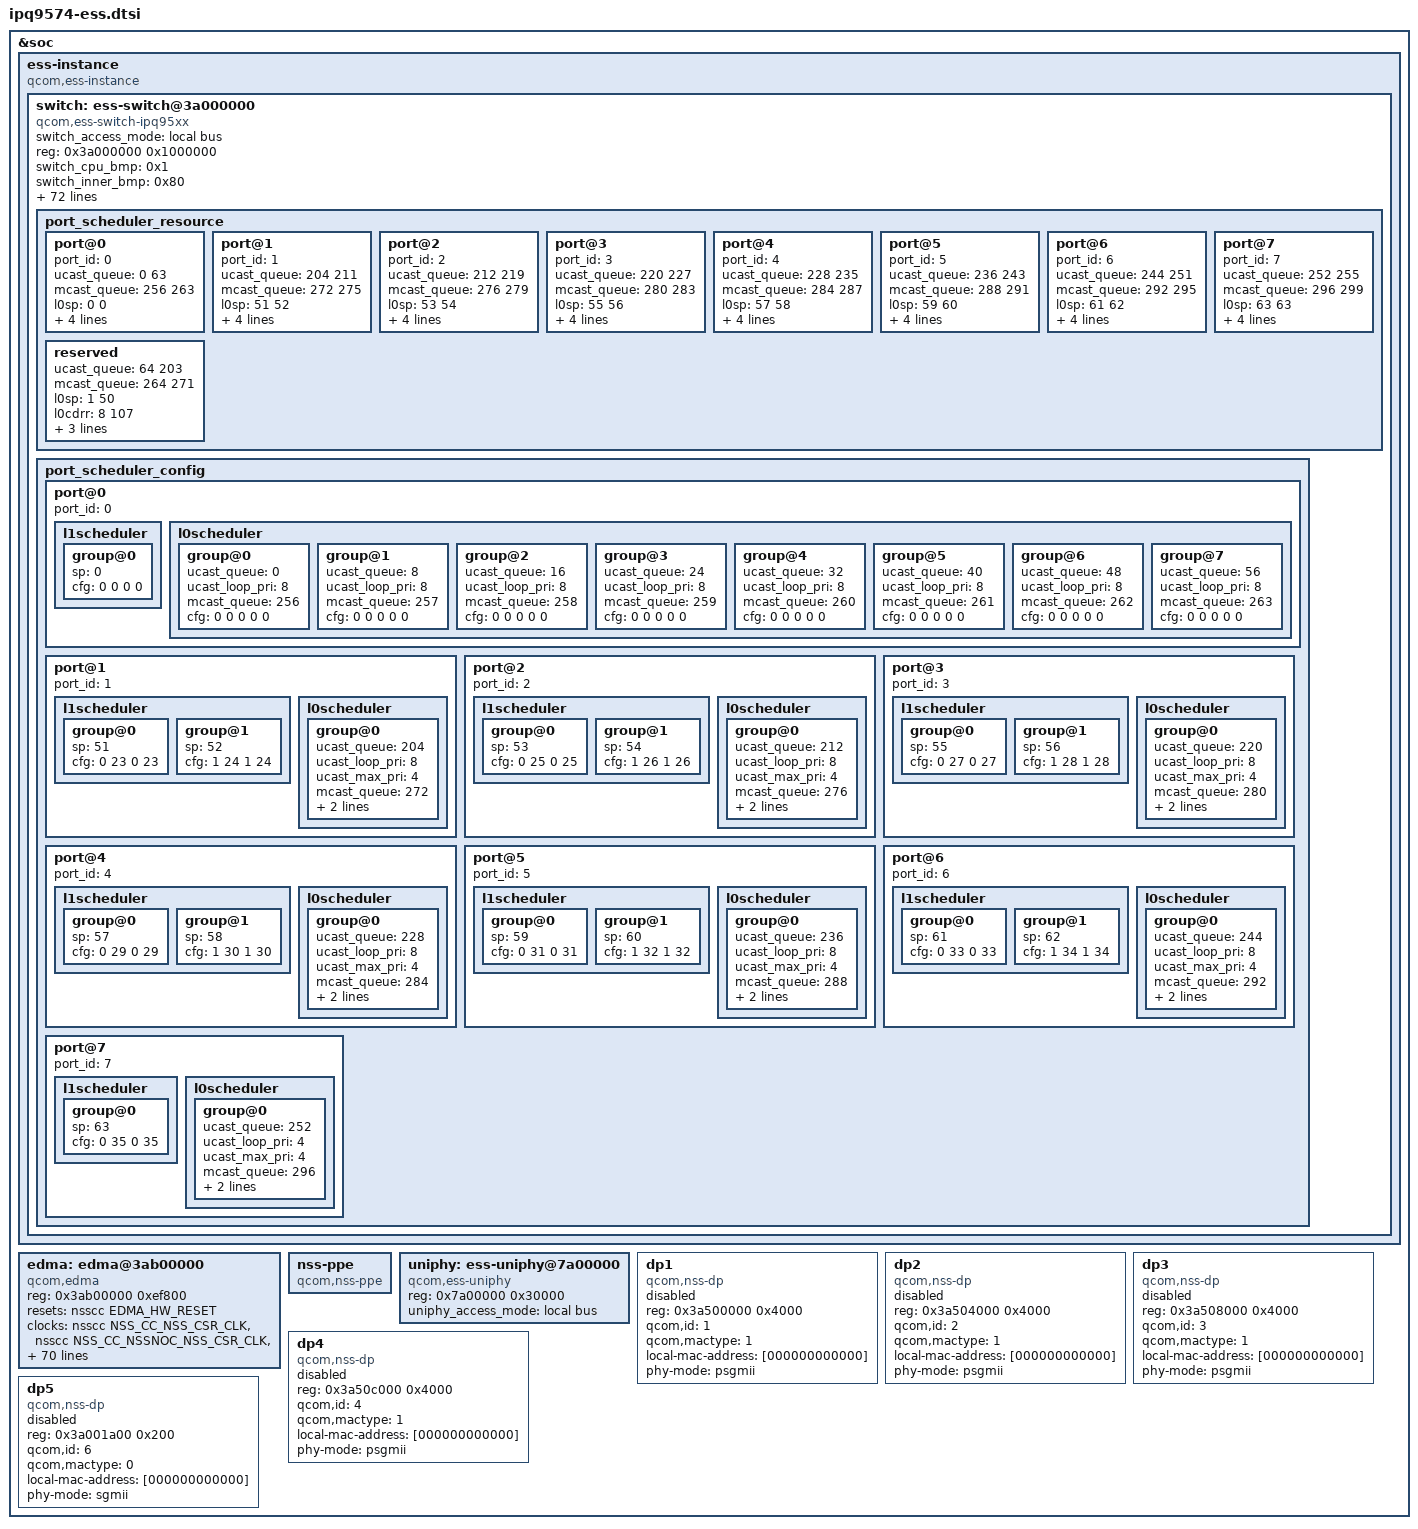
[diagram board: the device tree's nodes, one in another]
// #include <dt-bindings/reset/qcom,ipq9574-nsscc.h>

&soc {
	ess-instance {
		#address-cells = <1>;
		#size-cells = <1>;
		compatible = "qcom,ess-instance";

		switch: ess-switch@3a000000 {
			compatible = "qcom,ess-switch-ipq95xx";
			switch_access_mode = "local bus";
			reg = <0x3a000000 0x1000000>;
			switch_cpu_bmp = <0x1>;
			switch_inner_bmp = <0x80>;
			mdio-bus = <&mdio>;
			clocks = <&gcc GCC_CMN_12GPLL_AHB_CLK>,
				<&gcc GCC_CMN_12GPLL_SYS_CLK>,
				<&gcc GCC_UNIPHY0_AHB_CLK>,
				<&gcc GCC_UNIPHY0_SYS_CLK>,
				<&gcc GCC_UNIPHY1_AHB_CLK>,
				<&gcc GCC_UNIPHY1_SYS_CLK>,
				<&gcc GCC_UNIPHY2_AHB_CLK>,
				<&gcc GCC_UNIPHY2_SYS_CLK>,
				<&gcc GCC_NSSNOC_NSSCC_CLK>,
				<&gcc GCC_NSSCC_CLK>,
				<&gcc GCC_NSSNOC_SNOC_1_CLK>,
				<&gcc GCC_NSSNOC_SNOC_CLK>,
				<&nsscc NSS_CC_PORT1_MAC_CLK>,
				<&nsscc NSS_CC_PORT2_MAC_CLK>,
				<&nsscc NSS_CC_PORT3_MAC_CLK>,
				<&nsscc NSS_CC_PORT4_MAC_CLK>,
				<&nsscc NSS_CC_PORT5_MAC_CLK>,
				<&nsscc NSS_CC_PORT6_MAC_CLK>,
				<&nsscc NSS_CC_PPE_SWITCH_CLK>,
				<&nsscc NSS_CC_PPE_SWITCH_CFG_CLK>,
				<&nsscc NSS_CC_NSSNOC_PPE_CLK>,
				<&nsscc NSS_CC_NSSNOC_PPE_CFG_CLK>,
				<&nsscc NSS_CC_PPE_EDMA_CLK>,
				<&nsscc NSS_CC_PPE_EDMA_CFG_CLK>,
				<&nsscc NSS_CC_PPE_SWITCH_IPE_CLK>,
				<&nsscc NSS_CC_PPE_SWITCH_BTQ_CLK>,
				<&nsscc NSS_CC_PORT1_RX_CLK>,
				<&nsscc NSS_CC_PORT1_TX_CLK>,
				<&nsscc NSS_CC_PORT2_RX_CLK>,
				<&nsscc NSS_CC_PORT2_TX_CLK>,
				<&nsscc NSS_CC_PORT3_RX_CLK>,
				<&nsscc NSS_CC_PORT3_TX_CLK>,
				<&nsscc NSS_CC_PORT4_RX_CLK>,
				<&nsscc NSS_CC_PORT4_TX_CLK>,
				<&nsscc NSS_CC_PORT5_RX_CLK>,
				<&nsscc NSS_CC_PORT5_TX_CLK>,
				<&nsscc NSS_CC_PORT6_RX_CLK>,
				<&nsscc NSS_CC_PORT6_TX_CLK>,
				<&nsscc NSS_CC_UNIPHY_PORT1_RX_CLK>,
				<&nsscc NSS_CC_UNIPHY_PORT1_TX_CLK>,
				<&nsscc NSS_CC_UNIPHY_PORT2_RX_CLK>,
				<&nsscc NSS_CC_UNIPHY_PORT2_TX_CLK>,
				<&nsscc NSS_CC_UNIPHY_PORT3_RX_CLK>,
				<&nsscc NSS_CC_UNIPHY_PORT3_TX_CLK>,
				<&nsscc NSS_CC_UNIPHY_PORT4_RX_CLK>,
				<&nsscc NSS_CC_UNIPHY_PORT4_TX_CLK>,
				<&nsscc NSS_CC_UNIPHY_PORT5_RX_CLK>,
				<&nsscc NSS_CC_UNIPHY_PORT5_TX_CLK>,
				<&nsscc NSS_CC_UNIPHY_PORT6_RX_CLK>,
				<&nsscc NSS_CC_UNIPHY_PORT6_TX_CLK>,
				<&nsscc NSS_CC_PORT5_RX_CLK_SRC>,
				<&nsscc NSS_CC_PORT5_TX_CLK_SRC>;
			clock-names = "cmn_ahb_clk",
				"cmn_sys_clk",
				"uniphy0_ahb_clk",
				"uniphy0_sys_clk",
				"uniphy1_ahb_clk",
				"uniphy1_sys_clk",
				"uniphy2_ahb_clk",
				"uniphy2_sys_clk",
				"gcc_nssnoc_nsscc_clk",
				"gcc_nsscc_clk",
				"gcc_nssnoc_snoc_1_clk",
				"gcc_nssnoc_snoc_clk",
				"port1_mac_clk",
				"port2_mac_clk",
				"port3_mac_clk",
				"port4_mac_clk",
				"port5_mac_clk",
				"port6_mac_clk",
				"nss_ppe_clk",
				"nss_ppe_cfg_clk",
				"nssnoc_ppe_clk",
				"nssnoc_ppe_cfg_clk",
				"nss_edma_clk",
				"nss_edma_cfg_clk",
				"nss_ppe_ipe_clk",
				"nss_ppe_btq_clk",
				"nss_port1_rx_clk", "nss_port1_tx_clk",
				"nss_port2_rx_clk", "nss_port2_tx_clk",
				"nss_port3_rx_clk", "nss_port3_tx_clk",
				"nss_port4_rx_clk", "nss_port4_tx_clk",
				"nss_port5_rx_clk", "nss_port5_tx_clk",
				"nss_port6_rx_clk", "nss_port6_tx_clk",
				"uniphy0_port1_rx_clk",
				"uniphy0_port1_tx_clk",
				"uniphy0_port2_rx_clk",
				"uniphy0_port2_tx_clk",
				"uniphy0_port3_rx_clk",
				"uniphy0_port3_tx_clk",
				"uniphy0_port4_rx_clk",
				"uniphy0_port4_tx_clk",
				"uniphy0_port5_rx_clk",
				"uniphy0_port5_tx_clk",
				"uniphy2_port6_rx_clk",
				"uniphy2_port6_tx_clk",
				"nss_port5_rx_clk_src",
				"nss_port5_tx_clk_src";
			resets = <&nsscc PPE_FULL_RESET>,
				<&nsscc UNIPHY0_SOFT_RESET>,
				<&gcc GCC_UNIPHY0_XPCS_RESET>,
				<&nsscc UNIPHY_PORT5_ARES>,
				<&gcc GCC_UNIPHY1_XPCS_RESET>,
				<&nsscc UNIPHY_PORT6_ARES>,
				<&gcc GCC_UNIPHY2_XPCS_RESET>,
				<&nsscc UNIPHY_PORT1_ARES>,
				<&nsscc UNIPHY_PORT2_ARES>,
				<&nsscc UNIPHY_PORT3_ARES>,
				<&nsscc UNIPHY_PORT4_ARES>,
				<&gcc GCC_UNIPHY0_SYS_RESET>,
				<&gcc GCC_UNIPHY1_SYS_RESET>,
				<&gcc GCC_UNIPHY2_SYS_RESET>,
				<&nsscc NSSPORT1_RESET>,
				<&nsscc NSSPORT2_RESET>,
				<&nsscc NSSPORT3_RESET>,
				<&nsscc NSSPORT4_RESET>,
				<&nsscc NSSPORT5_RESET>,
				<&nsscc NSSPORT6_RESET>,
				<&nsscc PORT1_MAC_ARES>,
				<&nsscc PORT2_MAC_ARES>,
				<&nsscc PORT3_MAC_ARES>,
				<&nsscc PORT4_MAC_ARES>,
				<&nsscc PORT5_MAC_ARES>,
				<&nsscc PORT6_MAC_ARES>;
			reset-names = "ppe_rst",
				"uniphy0_soft_rst",
				"uniphy0_xpcs_rst",
				"uniphy1_soft_rst",
				"uniphy1_xpcs_rst",
				"uniphy2_soft_rst",
				"uniphy2_xpcs_rst",
				"uniphy0_port1_dis",
				"uniphy0_port2_dis",
				"uniphy0_port3_dis",
				"uniphy0_port4_dis",
				"uniphy0_sys_rst",
				"uniphy1_sys_rst",
				"uniphy2_sys_rst",
				"nss_port1_rst",
				"nss_port2_rst",
				"nss_port3_rst",
				"nss_port4_rst",
				"nss_port5_rst",
				"nss_port6_rst",
				"nss_port1_mac_rst",
				"nss_port2_mac_rst",
				"nss_port3_mac_rst",
				"nss_port4_mac_rst",
				"nss_port5_mac_rst",
				"nss_port6_mac_rst";
			port_scheduler_resource {
				port@0 {
					port_id = <0>;
					ucast_queue = <0 63>;
					mcast_queue = <256 263>;
					l0sp = <0 0>;
					l0cdrr = <0 7>;
					l0edrr = <0 7>;
					l1cdrr = <0 0>;
					l1edrr = <0 0>;
				};
				port@1 {
					port_id = <1>;
					ucast_queue = <204 211>;
					mcast_queue = <272 275>;
					l0sp = <51 52>;
					l0cdrr = <108 115>;
					l0edrr = <108 115>;
					l1cdrr = <23 24>;
					l1edrr = <23 24>;
				};
				port@2 {
					port_id = <2>;
					ucast_queue = <212 219>;
					mcast_queue = <276 279>;
					l0sp = <53 54>;
					l0cdrr = <116 123>;
					l0edrr = <116 123>;
					l1cdrr = <25 26>;
					l1edrr = <25 26>;
				};
				port@3 {
					port_id = <3>;
					ucast_queue = <220 227>;
					mcast_queue = <280 283>;
					l0sp = <55 56>;
					l0cdrr = <124 131>;
					l0edrr = <124 131>;
					l1cdrr = <27 28>;
					l1edrr = <27 28>;
				};
				port@4 {
					port_id = <4>;
					ucast_queue = <228 235>;
					mcast_queue = <284 287>;
					l0sp = <57 58>;
					l0cdrr = <132 139>;
					l0edrr = <132 139>;
					l1cdrr = <29 30>;
					l1edrr = <29 30>;
				};
				port@5 {
					port_id = <5>;
					ucast_queue = <236 243>;
					mcast_queue = <288 291>;
					l0sp = <59 60>;
					l0cdrr = <140 147>;
					l0edrr = <140 147>;
					l1cdrr = <31 32>;
					l1edrr = <31 32>;
				};
				port@6 {
					port_id = <6>;
					ucast_queue = <244 251>;
					mcast_queue = <292 295>;
					l0sp = <61 62>;
					l0cdrr = <148 155>;
					l0edrr = <148 155>;
					l1cdrr = <33 34>;
					l1edrr = <33 34>;
				};
				port@7 {
					port_id = <7>;
					ucast_queue = <252 255>;
					mcast_queue = <296 299>;
					l0sp = <63 63>;
					l0cdrr = <156 159>;
					l0edrr = <156 159>;
					l1cdrr = <35 35>;
					l1edrr = <35 35>;
				};
				reserved {
					ucast_queue = <64 203>;
					mcast_queue = <264 271>;
					l0sp = <1 50>;
					l0cdrr = <8 107>;
					l0edrr = <8 107>;
					l1cdrr = <1 22>;
					l1edrr = <1 22>;
				};
			};
			port_scheduler_config {
				port@0 {
					port_id = <0>;
					l1scheduler {
						group@0 {
							/* L0 SP */
							sp = <0>;
							/* cpri cdrr epri edrr */
							cfg = <0 0 0 0>;
						};
					};
					l0scheduler {
						group@0 {
							/* unicast queue */
							ucast_queue = <0>;
							ucast_loop_pri = <8>;
							/* multicast queue */
							mcast_queue = <256>;
							/* sp cpri cdrr epri edrr */
							cfg = <0 0 0 0 0>;
						};
						group@1 {
							ucast_queue = <8>;
							ucast_loop_pri = <8>;
							mcast_queue = <257>;
							cfg = <0 0 0 0 0>;
						};
						group@2 {
							ucast_queue = <16>;
							ucast_loop_pri = <8>;
							mcast_queue = <258>;
							cfg = <0 0 0 0 0>;
						};
						group@3 {
							ucast_queue = <24>;
							ucast_loop_pri = <8>;
							mcast_queue = <259>;
							cfg = <0 0 0 0 0>;
						};
						group@4 {
							ucast_queue = <32>;
							ucast_loop_pri = <8>;
							mcast_queue = <260>;
							cfg = <0 0 0 0 0>;
						};
						group@5 {
							ucast_queue = <40>;
							ucast_loop_pri = <8>;
							mcast_queue = <261>;
							cfg = <0 0 0 0 0>;
						};
						group@6 {
							ucast_queue = <48>;
							ucast_loop_pri = <8>;
							mcast_queue = <262>;
							cfg = <0 0 0 0 0>;
						};
						group@7 {
							ucast_queue = <56>;
							ucast_loop_pri = <8>;
							mcast_queue = <263>;
							cfg = <0 0 0 0 0>;
						};
					};
				};
				port@1 {
					port_id = <1>;
					l1scheduler {
						group@0 {
							sp = <51>;
							cfg = <0 23 0 23>;
						};
						group@1 {
							sp = <52>;
							cfg = <1 24 1 24>;
						};
					};
					l0scheduler {
						group@0 {
							ucast_queue = <204>;
							ucast_loop_pri = <8>;
							/* max priority per SP */
							ucast_max_pri = <4>;
							mcast_queue = <272>;
							mcast_loop_pri = <4>;
							cfg = <51 0 108 0 108>;
						};
					};
				};
				port@2 {
					port_id = <2>;
					l1scheduler {
						group@0 {
							sp = <53>;
							cfg = <0 25 0 25>;
						};
						group@1 {
							sp = <54>;
							cfg = <1 26 1 26>;
						};
					};
					l0scheduler {
						group@0 {
							ucast_queue = <212>;
							ucast_loop_pri = <8>;
							ucast_max_pri = <4>;
							mcast_queue = <276>;
							mcast_loop_pri = <4>;
							cfg = <53 0 116 0 116>;
						};
					};
				};
				port@3 {
					port_id = <3>;
					l1scheduler {
						group@0 {
							sp = <55>;
							cfg = <0 27 0 27>;
						};
						group@1 {
							sp = <56>;
							cfg = <1 28 1 28>;
						};
					};
					l0scheduler {
						group@0 {
							ucast_queue = <220>;
							ucast_loop_pri = <8>;
							ucast_max_pri = <4>;
							mcast_queue = <280>;
							mcast_loop_pri = <4>;
							cfg = <55 0 124 0 124>;
						};
					};
				};
				port@4 {
					port_id = <4>;
					l1scheduler {
						group@0 {
							sp = <57>;
							cfg = <0 29 0 29>;
						};
						group@1 {
							sp = <58>;
							cfg = <1 30 1 30>;
						};
					};
					l0scheduler {
						group@0 {
							ucast_queue = <228>;
							ucast_loop_pri = <8>;
							ucast_max_pri = <4>;
							mcast_queue = <284>;
							mcast_loop_pri = <4>;
							cfg = <57 0 132 0 132>;
						};
					};
				};
				port@5 {
					port_id = <5>;
					l1scheduler {
						group@0 {
							sp = <59>;
							cfg = <0 31 0 31>;
						};
						group@1 {
							sp = <60>;
							cfg = <1 32 1 32>;
						};
					};
					l0scheduler {
						group@0 {
							ucast_queue = <236>;
							ucast_loop_pri = <8>;
							ucast_max_pri = <4>;
							mcast_queue = <288>;
							mcast_loop_pri = <4>;
							cfg = <59 0 140 0 140>;
						};
					};
				};
				port@6 {
					port_id = <6>;
					l1scheduler {
						group@0 {
							sp = <61>;
							cfg = <0 33 0 33>;
						};
						group@1 {
							sp = <62>;
							cfg = <1 34 1 34>;
						};
					};
					l0scheduler {
						group@0 {
							ucast_queue = <244>;
							ucast_loop_pri = <8>;
							ucast_max_pri = <4>;
							mcast_queue = <292>;
							mcast_loop_pri = <4>;
							cfg = <61 0 148 0 148>;
						};
					};
				};
				port@7 {
					port_id = <7>;
					l1scheduler {
						group@0 {
							sp = <63>;
							cfg = <0 35 0 35>;
						};
					};
					l0scheduler {
						group@0 {
							ucast_queue = <252>;
							ucast_loop_pri = <4>;
							ucast_max_pri = <4>;
							mcast_queue = <296>;
							mcast_loop_pri = <4>;
							cfg = <63 0 156 0 156>;
						};
					};
				};
			};
		};
	};

	edma: edma@3ab00000 {
		compatible = "qcom,edma";
		reg = <0x3ab00000 0xef800>;
		reg-names = "edma-reg-base";
		resets = <&nsscc EDMA_HW_RESET>;
		reset-names = "edma_rst";
		clocks = <&nsscc NSS_CC_NSS_CSR_CLK>,
				<&nsscc NSS_CC_NSSNOC_NSS_CSR_CLK>,
				<&nsscc NSS_CC_IMEM_QSB_CLK>,
				<&nsscc NSS_CC_NSSNOC_IMEM_QSB_CLK>,
				<&nsscc NSS_CC_IMEM_AHB_CLK>,
				<&nsscc NSS_CC_NSSNOC_IMEM_AHB_CLK>,
				<&gcc GCC_MEM_NOC_NSSNOC_CLK>,
				<&gcc GCC_NSS_TBU_CLK>,
				<&gcc GCC_NSS_TS_CLK>,
				<&gcc GCC_NSSCC_CLK>,
				<&gcc GCC_NSSCFG_CLK>,
				<&gcc GCC_NSSNOC_ATB_CLK>,
				<&gcc GCC_NSSNOC_MEM_NOC_1_CLK>,
				<&gcc GCC_NSSNOC_MEMNOC_CLK>,
				<&gcc GCC_NSSNOC_NSSCC_CLK>,
				<&gcc GCC_NSSNOC_PCNOC_1_CLK>,
				<&gcc GCC_NSSNOC_QOSGEN_REF_CLK>,
				<&gcc GCC_NSSNOC_SNOC_1_CLK>,
				<&gcc GCC_NSSNOC_SNOC_CLK>,
				<&gcc GCC_NSSNOC_TIMEOUT_REF_CLK>,
				<&gcc GCC_NSSNOC_XO_DCD_CLK>;
		clock-names = "nss-csr-clk", "nss-nssnoc-csr-clk",
				"nss-imem-qsb-clk", "nss-nssnoc-imem-qsb-clk",
				"nss-imem-ahb-clk", "nss-nssnoc-imem-ahb-clk",
				"nss-mem-noc-nssnoc-clk", "nss-tbu-clk", "nss-ts-clk",
				"nss-nsscc-clk", "nss-nsscfg-clk", "nss-nsscnoc-atb-clk",
				"nss-nssnoc-mem-noc-1-clk", "nss-nssnoc-memnoc-clk", "nss-nssnoc-nsscc-clk",
				"nss-nssnoc-pcnoc-1-clk", "nss-nssnoc-qosgen-ref-clk", "nss-nssnoc-snoc-1-clk",
				"nss-nssnoc-snoc-clk", "nss-nssnoc-timeout-ref-clk", "nss-nssnoc-xo-dcd-clk";

		interrupts = <GIC_SPI 367 IRQ_TYPE_LEVEL_HIGH>,
				<GIC_SPI 368 IRQ_TYPE_LEVEL_HIGH>,
				<GIC_SPI 369 IRQ_TYPE_LEVEL_HIGH>,
				<GIC_SPI 370 IRQ_TYPE_LEVEL_HIGH>,
				<GIC_SPI 371 IRQ_TYPE_LEVEL_HIGH>,
				<GIC_SPI 372 IRQ_TYPE_LEVEL_HIGH>,
				<GIC_SPI 373 IRQ_TYPE_LEVEL_HIGH>,
				<GIC_SPI 374 IRQ_TYPE_LEVEL_HIGH>,
				<GIC_SPI 375 IRQ_TYPE_LEVEL_HIGH>,
				<GIC_SPI 376 IRQ_TYPE_LEVEL_HIGH>,
				<GIC_SPI 377 IRQ_TYPE_LEVEL_HIGH>,
				<GIC_SPI 378 IRQ_TYPE_LEVEL_HIGH>,
				<GIC_SPI 379 IRQ_TYPE_LEVEL_HIGH>,
				<GIC_SPI 380 IRQ_TYPE_LEVEL_HIGH>,
				<GIC_SPI 381 IRQ_TYPE_LEVEL_HIGH>,
				<GIC_SPI 382 IRQ_TYPE_LEVEL_HIGH>,
				<GIC_SPI 383 IRQ_TYPE_LEVEL_HIGH>,
				<GIC_SPI 384 IRQ_TYPE_LEVEL_HIGH>,
				<GIC_SPI 509 IRQ_TYPE_LEVEL_HIGH>,
				<GIC_SPI 508 IRQ_TYPE_LEVEL_HIGH>,
				<GIC_SPI 507 IRQ_TYPE_LEVEL_HIGH>,
				<GIC_SPI 506 IRQ_TYPE_LEVEL_HIGH>,
				<GIC_SPI 505 IRQ_TYPE_LEVEL_HIGH>,
				<GIC_SPI 504 IRQ_TYPE_LEVEL_HIGH>,
				<GIC_SPI 503 IRQ_TYPE_LEVEL_HIGH>,
				<GIC_SPI 502 IRQ_TYPE_LEVEL_HIGH>,
				<GIC_SPI 501 IRQ_TYPE_LEVEL_HIGH>,
				<GIC_SPI 500 IRQ_TYPE_LEVEL_HIGH>,
				<GIC_SPI 351 IRQ_TYPE_LEVEL_HIGH>,
				<GIC_SPI 352 IRQ_TYPE_LEVEL_HIGH>,
				<GIC_SPI 353 IRQ_TYPE_LEVEL_HIGH>,
				<GIC_SPI 354 IRQ_TYPE_LEVEL_HIGH>,
				<GIC_SPI 261 IRQ_TYPE_LEVEL_HIGH>;
		interrupt-names = "tx-complete-ring-4", "tx-complete-ring-5",
				"tx-complete-ring-6", "tx-complete-ring-7",
				"tx-complete-ring-8", "tx-complete-ring-9",
				"tx-complete-ring-10", "tx-complete-ring-11",
				"tx-complete-ring-12", "tx-complete-ring-13",
				"tx-complete-ring-14", "tx-complete-ring-15",
				"tx-complete-ring-16", "tx-complete-ring-17",
				"tx-complete-ring-18", "tx-complete-ring-19",
				"tx-complete-ring-20", "tx-complete-ring-21",
				"tx-complete-ring-22", "tx-complete-ring-23",
				"tx-complete-ring-24", "tx-complete-ring-25",
				"tx-complete-ring-26", "tx-complete-ring-27",
				"tx-complete-ring-28", "tx-complete-ring-29",
				"tx-complete-ring-30", "tx-complete-ring-31",
				"rx-desc-ring-20", "rx-desc-ring-21",
				"rx-desc-ring-22", "rx-desc-ring-23",
				"misc-error";

		qcom,txdesc-ring-start = <4>;
		qcom,txdesc-rings = <28>;
		qcom,txcmpl-ring-start = <4>;
		qcom,txcmpl-rings = <28>;
		qcom,rxfill-ring-start = <4>;
		qcom,rxfill-rings = <4>;
		qcom,rxdesc-ring-start = <20>;
		qcom,rxdesc-rings = <4>;
		qcom,rx-page-mode = <0>;
		qcom,tx-map-priority-level = <1>;
		qcom,rx-map-priority-level = <1>;
		qcom,txdesc-map = <8 9 10 11>,
				  <12 13 14 15>,
				  <16 17 18 19>,
				  <20 21 22 23>,
				  <24 25 26 27>,
				  <28 29 30 31>,
				  <4 5 6 7>;
		qcom,txdesc-fc-grp-map = <1 2 3 4 5 6>;
		qcom,rxdesc-map = <20 21 22 23>;

		// Quantities pulled directly from my ass
		qcom,rx-queue-start = <0>;
		qcom,rx-ring-queue-map = <0 1 2 3 4 5 6 7 8>,
					 <0 1 2 3 4 5 6 7 8>,
					 <0 1 2 3 4 5 6 7 8>,
					 <0 1 2 3 4 5 6 7 8>;
	};

	nss-ppe {
		compatible = "qcom,nss-ppe";
	};

	uniphy: ess-uniphy@7a00000 {
		compatible = "qcom,ess-uniphy";
		reg = <0x7a00000 0x30000>;
		uniphy_access_mode = "local bus";
	};

	dp1: dp1 {
		compatible = "qcom,nss-dp";
		reg = <0x3a500000 0x4000>;
		qcom,id = <1>;
		qcom,mactype = <1>;
		local-mac-address = [000000000000];
		phy-mode = "psgmii";
		status = "disabled";
	};

	dp2: dp2 {
		compatible = "qcom,nss-dp";
		reg = <0x3a504000 0x4000>;
		qcom,id = <2>;
		qcom,mactype = <1>;
		local-mac-address = [000000000000];
		phy-mode = "psgmii";
		status = "disabled";
	};

	dp3: dp3 {
		compatible = "qcom,nss-dp";
		reg = <0x3a508000 0x4000>;
		qcom,id = <3>;
		qcom,mactype = <1>;
		local-mac-address = [000000000000];
		phy-mode = "psgmii";
		status = "disabled";
	};

	dp4: dp4 {
		compatible = "qcom,nss-dp";
		reg = <0x3a50c000 0x4000>;
		qcom,id = <4>;
		qcom,mactype = <1>;
		local-mac-address = [000000000000];
		phy-mode = "psgmii";
		status = "disabled";
	};

	dp5: dp5 {
		compatible = "qcom,nss-dp";
		reg = <0x3a001a00 0x200>;
		qcom,id = <6>;
		qcom,mactype = <0>;
		local-mac-address = [000000000000];
		phy-mode = "sgmii";
		status = "disabled";
	};
};
